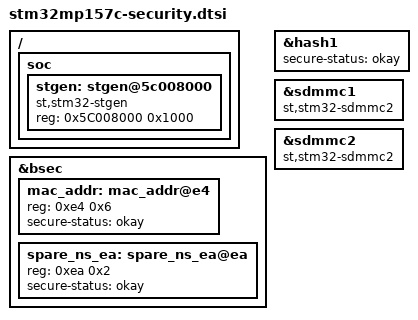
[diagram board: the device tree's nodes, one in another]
/*
 * Copyright (c) 2017-2019, STMicroelectronics - All Rights Reserved
 *
 * SPDX-License-Identifier:	GPL-2.0+	BSD-3-Clause
 */

/ {
	soc {
		stgen: stgen@5c008000 {
			compatible = "st,stm32-stgen";
			reg = <0x5C008000 0x1000>;
			status = "okay";
		};
	};
};

&bsec {
	mac_addr: mac_addr@e4 {
		reg = <0xe4 0x6>;
		status = "okay";
		secure-status = "okay";
	};
	/* Spare field to align on 32-bit OTP granularity  */
	spare_ns_ea: spare_ns_ea@ea {
		reg = <0xea 0x2>;
		status = "okay";
		secure-status = "okay";
	};
};

&hash1 {
	secure-status = "okay";
};

&sdmmc1 {
	compatible = "st,stm32-sdmmc2";
};

&sdmmc2 {
	compatible = "st,stm32-sdmmc2";
};
